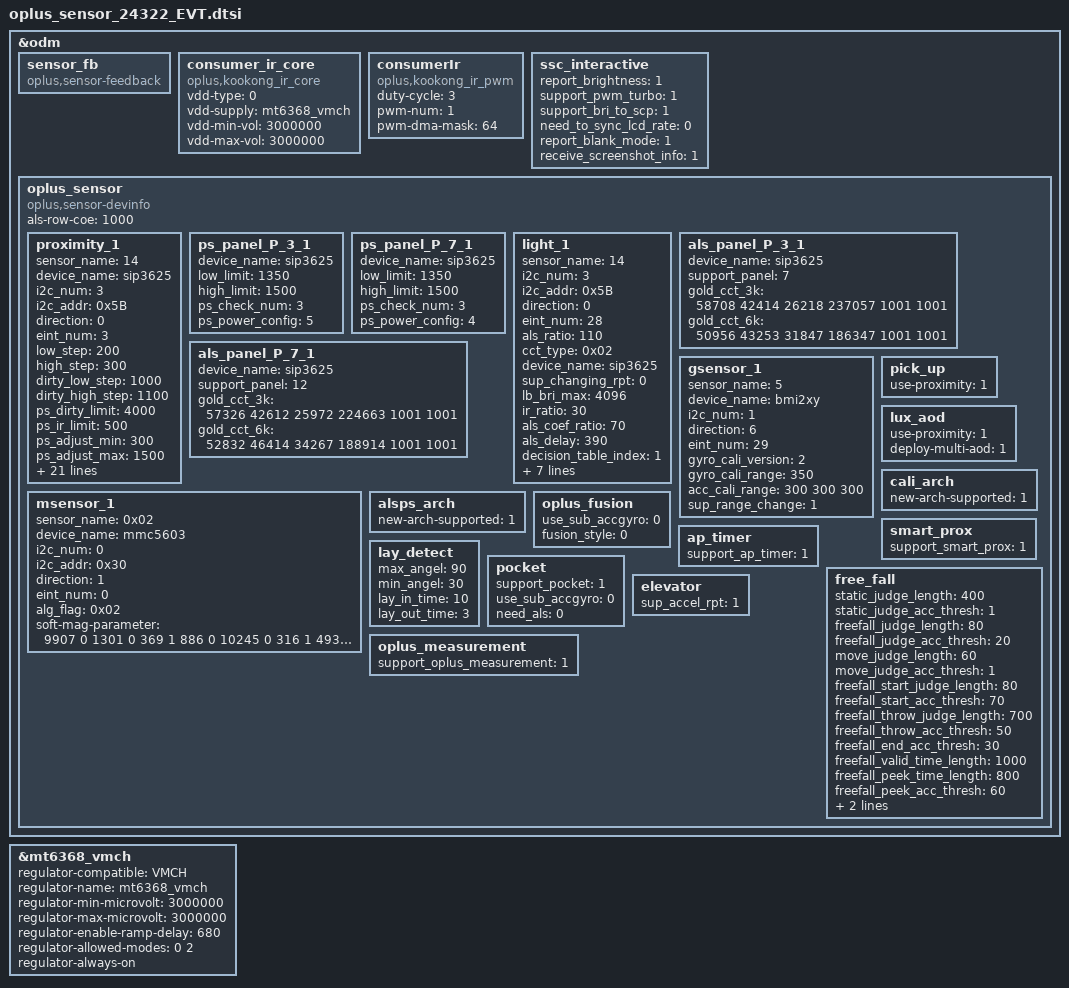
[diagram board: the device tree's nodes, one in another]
&odm {
	sensor_fb: sensor_fb {
		compatible = "oplus,sensor-feedback";
	};
	consumer_ir_core: consumer_ir_core {
		compatible = "oplus,kookong_ir_core";
		status = "okay";
		vdd-type = <0>;  /*0: internal LDO , 1: external LDO , 2: NO VDD */
		vdd-supply = <&mt6368_vmch>;
		vdd-min-vol = <3000000>;
		vdd-max-vol = <3000000>;
	};
	consumerIr: consumerIr {
		compatible = "oplus,kookong_ir_pwm";
		status = "okay";
		duty-cycle = <3>;
		pwm-num = <1>;
		pwm-dma-mask = <64>;
	};
	ssc_interactive: ssc_interactive {
		report_brightness = <1>;
		support_pwm_turbo = <1>;
		support_bri_to_scp = <1>;
		need_to_sync_lcd_rate = <0>;
		report_blank_mode = <1>;
		receive_screenshot_info = <1>;
	};
	oplus_sensor:oplus_sensor {
		compatible = "oplus,sensor-devinfo";
		als-row-coe = <1000>;
		/* sensor start */
		/*
			enum {
			LIS3DH,
			LSM6DS3,
			BMI160,
			LIS2HH12,
			LSM6DSM,
			BMI2XY,//5
			LSM6DSO,
			ICM4X6XX,
			ICM4263X,
			ICM4N607,
			BMI22X,
			SC7A20,
			MC34X9,
			BMA4XY,
			STK8329,
			BMI3XY,
			ICM456XY,//16
		};
		*/
		proximity_1: proximity_1 {
			status = "okay";
			sensor_name = <14>; // SIP3625
			device_name = "sip3625";
			i2c_num = <3>;
			i2c_addr = <0x5B>;
			direction = <0>;
			eint_num = <3>;
			low_step = <200>;
			high_step = <300>;
			dirty_low_step = <1000>;
			dirty_high_step = <1100>;
			ps_dirty_limit = <4000>;
			ps_ir_limit = <500>;
			ps_adjust_min = <300>;
			ps_adjust_max = <1500>;
			sampling_count = <5>;
			step_max = <400>;
			step_min = <100>;
			step_div = <2000>;
			anti_shake_delta = <120>;
			dynamic_cali_max = <2000>;
			raw2offset_radio = <5000>;
			offset_max = <15000>;
			offset_range_min = <0>;
			offset_range_max = <65534>;
			force_cali_limit = <5116>;
			cali_jitter_limit = <70>;
			cal_offset_margin = <3000>;
			60hz_psd_us = <13500>;
			90hz_psd_us = <7944>;
			120hz_psd_us = <5166>;
			ps_mid_filter = <0>;
			need_to_sync_lcd_rate = <0>;
			dmc_flt_thr = <100>;
			multi_oft_level = <3>;
			multi_oft_coef = <130 26 1>;
		};
		ps_panel_P_3_1: ps_panel_P_3_1 {
			status = "okay";
			device_name = "sip3625";
			low_limit = <1350>;
			high_limit = <1500>;
			ps_check_num = <3>;
			ps_power_config = <5>;
		};
		ps_panel_P_7_1: ps_panel_P_7_1 {
			status = "okay";
			device_name = "sip3625";
			low_limit = <1350>;
			high_limit = <1500>;
			ps_check_num = <3>;
			ps_power_config = <4>;
		};
		light_1: light_1 {
			status = "okay";
			sensor_name = <14>;//SIP3625
			i2c_num = <3>;
			i2c_addr = <0x5B>;
			direction = <0>;
			eint_num = <28>;
			als_ratio = <110>;
			cct_type = <0x02>; //0x01 CCT_NORMAL 0x02 CCT_WISE
			device_name = "sip3625";
			sup_changing_rpt = <0>;
			lb_bri_max = <4096>;
			ir_ratio = <30>; // *100
			als_coef_ratio = <70>; // *100
			als_delay = <390>;
			decision_table_index = <1>;
			available_sensor = <14>;
			gold_cct_factor = <941 946 924 966 1001 1001>;
			high_pwm_cct = <1>;
			als_timer_ms = <100>;
			als_buffer_length = <2>;
			need_gain_cali = <1>;
			atime = <8330>;
		};
		als_panel_P_3_1: als_panel_P_3_1 {
			status = "okay";
			device_name = "sip3625";
			support_panel = <7>; // 1-SAMSUNG, 2-BOE, 3-TIANMA, 4-NT36672C, 5-HX83112F, 6-TM, 7-P_3, 8-P_B
			gold_cct_3k = <58708  42414 26218 237057 1001 1001>;
			gold_cct_6k = <50956 43253 31847 186347 1001 1001>;
		};
		als_panel_P_7_1: als_panel_P_7_1 {
			status = "okay";
			device_name = "sip3625";
			support_panel = <12>; // 1-SAMSUNG, 2-BOE, 3-TIANMA, 4-NT36672C, 5-HX83112F, 6-TM, 7-P_3, 8-P_B
			gold_cct_3k = <57326 42612 25972 224663 1001 1001>;
			gold_cct_6k = <52832 46414 34267 188914 1001 1001>;
		};
		gsensor_1: gsensor_1 {
			status = "okay";
			sensor_name = <5>; // BMI2XY
			device_name = "bmi2xy";
			i2c_num = <1>;
			direction = <6>;
			eint_num = <29>;
			gyro_cali_version= <2>;
			gyro_cali_range =<350>;
			acc_cali_range= <300 300 300>;
			sup_range_change = <1>;
		};
		/*
		enum {
			AKM09911,
			MMC3530,
			MMC5603,
			MXG4300,
			AKM09918,
		};
		*/
		msensor_1: msensor_1 {
			status = "okay";
			sensor_name = <0x02>; // MMC5603
			device_name = "mmc5603";
			i2c_num = <0>;
			i2c_addr = <0x30>;
			direction = <1>;
			eint_num = <0>;
			alg_flag = <0x02>;
			soft-mag-parameter = <9907 0 1301 0 369 1 886 0 10245 0 316 1 493 0 485 1 10518 0>;
		};

		pick_up: pick_up {
			status = "okay";
			use-proximity = <1>;
		};
		lux_aod: lux_aod {
			status = "okay";
			use-proximity = <1>;
			deploy-multi-aod = <1>;
		};
		cali_arch: cali_arch {
			status = "okay";
			new-arch-supported = <1>;
		};
		alsps_arch: alsps_arch {
			status = "okay";
			new-arch-supported = <1>;
		};
		oplus_fusion: oplus_fusion {
			status = "okay";
			use_sub_accgyro = <0>;
			fusion_style = <0>;
		};
		smart_prox: smart_prox {
			status = "okay";
			support_smart_prox = <1>;
		};
		ap_timer: ap_timer {
			status = "okay";
			support_ap_timer = <1>;
		};
		lay_detect: lay_detect{
			status = "okay";
			max_angel = <90>;
			min_angel = <30>;
			lay_in_time = <10>;
			lay_out_time = <3>;
		};
		pocket: pocket {
			status = "okay";
			support_pocket = <1>;
			use_sub_accgyro = <0>;
			need_als = <0>;
		};
		free_fall: free_fall{
			status = "okay";
			static_judge_length = <400>;
			static_judge_acc_thresh = <1>;
			freefall_judge_length = <80>;
			freefall_judge_acc_thresh = <20>;
			move_judge_length = <60>;
			move_judge_acc_thresh = <1>;
			freefall_start_judge_length  = <80>;
			freefall_start_acc_thresh = <70>;
			freefall_throw_judge_length = <700>;
			freefall_throw_acc_thresh = <50>;
			freefall_end_acc_thresh = <30>;
			freefall_valid_time_length = <1000>;
			freefall_peek_time_length = <800>;
			freefall_peek_acc_thresh = <60>;
			freefall_material_thresh = <900>;
			valid_peek_interval_thresh = <10000>;
		};
		oplus_measurement: oplus_measurement{
			status = "okay";
			support_oplus_measurement = <1>;
		};
		elevator: elevator{
			status = "okay";
			sup_accel_rpt = <1>;
		};
	};
/* sensor end */
};

&mt6368_vmch {
	regulator-compatible = "VMCH";
	regulator-name = "mt6368_vmch";
	regulator-min-microvolt = <3000000>;
	regulator-max-microvolt = <3000000>;
	regulator-enable-ramp-delay = <680>;
	regulator-allowed-modes = <0 2>;
	regulator-always-on;
};

